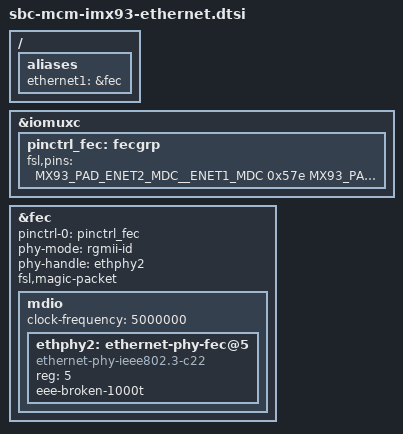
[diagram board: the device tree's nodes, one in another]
// SPDX-License-Identifier: (GPL-2.0+ OR MIT)
/*
 * Copyright 2026 CompuLab Ltd.
 */

/ {
	aliases {
		ethernet1 = &fec;
	};
};

&iomuxc {
	pinctrl_fec: fecgrp {
		fsl,pins = <
			MX93_PAD_ENET2_MDC__ENET1_MDC			0x57e
			MX93_PAD_ENET2_MDIO__ENET1_MDIO			0x57e
			MX93_PAD_ENET2_RD0__ENET1_RGMII_RD0		0x57e
			MX93_PAD_ENET2_RD1__ENET1_RGMII_RD1		0x57e
			MX93_PAD_ENET2_RD2__ENET1_RGMII_RD2		0x57e
			MX93_PAD_ENET2_RD3__ENET1_RGMII_RD3		0x57e
			MX93_PAD_ENET2_RXC__ENET1_RGMII_RXC		0x5fe
			MX93_PAD_ENET2_RX_CTL__ENET1_RGMII_RX_CTL	0x57e
			MX93_PAD_ENET2_TD0__ENET1_RGMII_TD0		0x57e
			MX93_PAD_ENET2_TD1__ENET1_RGMII_TD1		0x57e
			MX93_PAD_ENET2_TD2__ENET1_RGMII_TD2		0x57e
			MX93_PAD_ENET2_TD3__ENET1_RGMII_TD3		0x57e
			MX93_PAD_ENET2_TXC__ENET1_RGMII_TXC		0x5fe
			MX93_PAD_ENET2_TX_CTL__ENET1_RGMII_TX_CTL	0x57e
		>;
	};
};

&fec {
	pinctrl-names = "default";
	pinctrl-0 = <&pinctrl_fec>;
	phy-mode = "rgmii-id";
	phy-handle = <&ethphy2>;
	fsl,magic-packet;
	status = "okay";

	mdio {
		#address-cells = <1>;
		#size-cells = <0>;
		clock-frequency = <5000000>;

		ethphy2: ethernet-phy-fec@5 {
			compatible = "ethernet-phy-ieee802.3-c22";
			reg = <5>;
			eee-broken-1000t;
		};
	};
};
